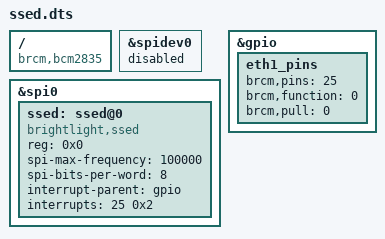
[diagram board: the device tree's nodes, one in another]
/dts-v1/;
/plugin/;
/ {
	compatible = "brcm,bcm2835";
	fragment@0 {
		target = <&spidev0>;
		__overlay__ {
			status = "disabled";
		};
	};
		
	fragment@1 {
		target = <&spi0>;
		__overlay__ {
			status = "okay";
			#address-cells = <1>;
			#size-cells = <0>;

			ssed: ssed@0 {
				compatible = "brightlight,ssed";
				reg = <0x0>;
				spi-max-frequency = <100000>;
				spi-bits-per-word = <8>;
				status = "okay";
				interrupt-parent = <&gpio>;
				interrupts = <25 0x2>;
			};
		};
	};

	fragment@2 {
		target = <&gpio>;
		__overlay__ {
			eth1_pins: eth1_pins {
				brcm,pins = <25>;
				brcm,function = <0>; /* in */
				brcm,pull = <0>; /* none */
			};
		};
	};
};
